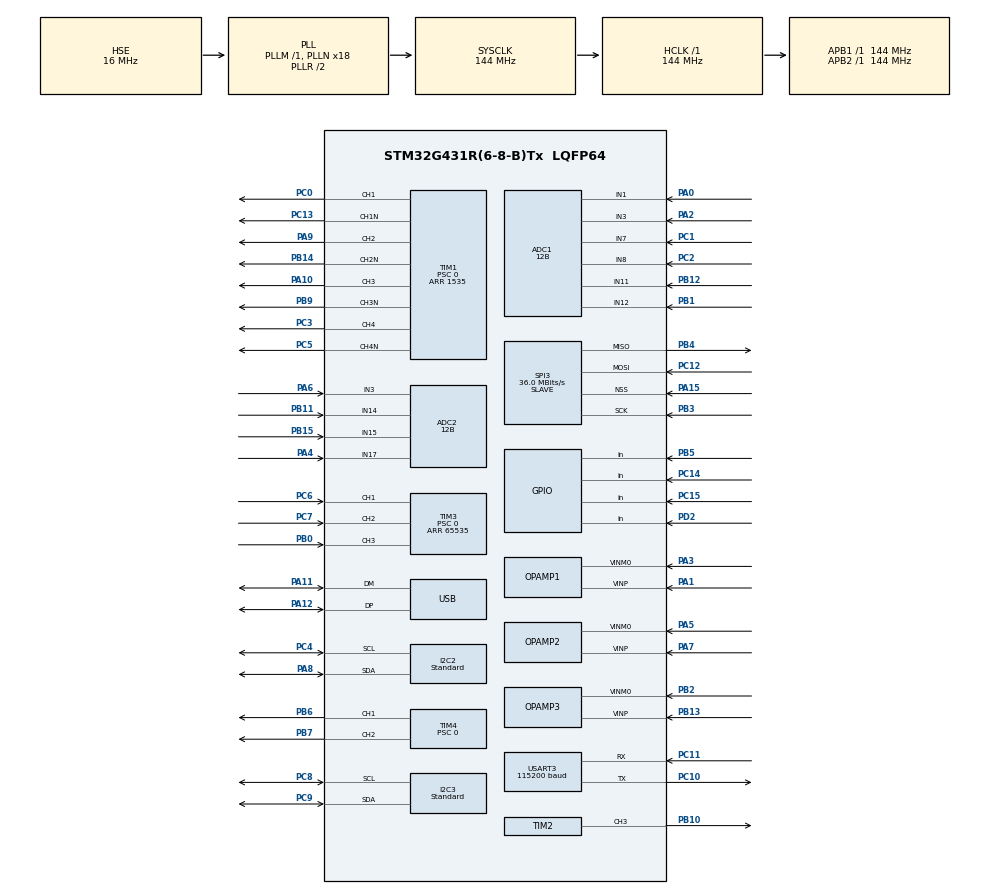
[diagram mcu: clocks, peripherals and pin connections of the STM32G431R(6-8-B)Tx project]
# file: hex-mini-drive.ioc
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ADC1.Channel-IN=ADC_CHANNEL_VOPAMP1
ADC1.Channel-IN1=ADC_CHANNEL_1
ADC1.Channel-IN11=ADC_CHANNEL_11
ADC1.Channel-IN12=ADC_CHANNEL_12
ADC1.Channel-IN3=ADC_CHANNEL_3
ADC1.Channel-IN7=ADC_CHANNEL_7
ADC1.Channel-IN8=ADC_CHANNEL_8
ADC1.ClockPrescaler=ADC_CLOCK_SYNC_PCLK_DIV4
ADC1.ContinuousConvMode=DISABLE
ADC1.DMAAccessModeView=DISABLED
ADC1.DMAContinuousRequests=DISABLE
ADC1.DataAlign=ADC_DATAALIGN_RIGHT
ADC1.DiscontinuousConvMode=DISABLE
ADC1.EOCSelection=ADC_EOC_SEQ_CONV
ADC1.EnableAnalogWatchDog1=false
ADC1.EnableAnalogWatchDog2=false
ADC1.EnableAnalogWatchDog3=false
ADC1.EnableInjectedConversion=ENABLE
ADC1.EnableInjectedOversampling=DISABLE
ADC1.EnableRegularConversion=DISABLE
ADC1.ExternalTrigInjecConv=ADC_EXTERNALTRIGINJEC_T1_TRGO2
ADC1.ExternalTrigInjecConvEdge=ADC_EXTERNALTRIGINJECCONV_EDGE_RISING
ADC1.GainCompensation=0
ADC1.InjNumberOfConversion=4
ADC1.InjectedChannel-1\#ChannelInjectedConversion=ADC_CHANNEL_TEMPSENSOR_ADC1
ADC1.InjectedChannel-2\#ChannelInjectedConversion=ADC_CHANNEL_1
ADC1.InjectedChannel-3\#ChannelInjectedConversion=ADC_CHANNEL_12
ADC1.InjectedChannel-4\#ChannelInjectedConversion=ADC_CHANNEL_3
ADC1.InjectedConvMode=None
ADC1.InjectedOffsetNumber-1\#ChannelInjectedConversion=ADC_OFFSET_NONE
ADC1.InjectedOffsetNumber-2\#ChannelInjectedConversion=ADC_OFFSET_NONE
ADC1.InjectedOffsetNumber-3\#ChannelInjectedConversion=ADC_OFFSET_NONE
ADC1.InjectedOffsetNumber-4\#ChannelInjectedConversion=ADC_OFFSET_NONE
ADC1.InjectedRank-1\#ChannelInjectedConversion=1
ADC1.InjectedRank-2\#ChannelInjectedConversion=2
ADC1.InjectedRank-3\#ChannelInjectedConversion=3
ADC1.InjectedRank-4\#ChannelInjectedConversion=4
ADC1.InjectedSamplingTime-1\#ChannelInjectedConversion=ADC_SAMPLETIME_92CYCLES_5
ADC1.InjectedSamplingTime-2\#ChannelInjectedConversion=ADC_SAMPLETIME_6CYCLES_5
ADC1.InjectedSamplingTime-3\#ChannelInjectedConversion=ADC_SAMPLETIME_6CYCLES_5
ADC1.InjectedSamplingTime-4\#ChannelInjectedConversion=ADC_SAMPLETIME_6CYCLES_5
ADC1.LowPowerAutoWait=DISABLE
ADC1.Mode=ADC_DUALMODE_REGSIMULT_INJECSIMULT
ADC1.Overrun=ADC_OVR_DATA_PRESERVED
ADC1.Resolution=ADC_RESOLUTION_12B
ADC1.ScanConvMode=ADC_SCAN_ENABLE
ADC1.TwoSamplingDelay=ADC_TWOSAMPLINGDELAY_1CYCLE
ADC1.injectedQueueMode=DISABLE
ADC1.master=1
ADC2.Channel-IN=ADC_CHANNEL_VOPAMP3_ADC2
ADC2.Channel-IN14=ADC_CHANNEL_14
ADC2.Channel-IN15=ADC_CHANNEL_15
ADC2.Channel-IN17=ADC_CHANNEL_17
ADC2.Channel-IN3=ADC_CHANNEL_3
ADC2.ClockPrescaler=ADC_CLOCK_SYNC_PCLK_DIV4
ADC2.ContinuousConvMode=DISABLE
ADC2.DMAAccessModeView=DISABLED
ADC2.DMAContinuousRequests=DISABLE
ADC2.DataAlign=ADC_DATAALIGN_RIGHT
ADC2.DiscontinuousConvMode=DISABLE
ADC2.EOCSelection=ADC_EOC_SINGLE_CONV
ADC2.EnableAnalogWatchDog1=false
ADC2.EnableAnalogWatchDog2=false
ADC2.EnableAnalogWatchDog3=false
ADC2.EnableInjectedConversion=ENABLE
ADC2.EnableInjectedOversampling=DISABLE
ADC2.EnableRegularConversion=DISABLE
ADC2.GainCompensation=0
ADC2.InjNumberOfConversion=4
ADC2.InjectedChannel-1\#ChannelInjectedConversion=ADC_CHANNEL_15
ADC2.InjectedChannel-2\#ChannelInjectedConversion=ADC_CHANNEL_3
ADC2.InjectedChannel-3\#ChannelInjectedConversion=ADC_CHANNEL_VOPAMP2
ADC2.InjectedChannel-4\#ChannelInjectedConversion=ADC_CHANNEL_VOPAMP3_ADC2
ADC2.InjectedConvMode=None
ADC2.InjectedOffsetNumber-1\#ChannelInjectedConversion=ADC_OFFSET_NONE
ADC2.InjectedOffsetNumber-2\#ChannelInjectedConversion=ADC_OFFSET_NONE
ADC2.InjectedOffsetNumber-3\#ChannelInjectedConversion=ADC_OFFSET_NONE
ADC2.InjectedOffsetNumber-4\#ChannelInjectedConversion=ADC_OFFSET_NONE
ADC2.InjectedRank-1\#ChannelInjectedConversion=1
ADC2.InjectedRank-2\#ChannelInjectedConversion=2
ADC2.InjectedRank-3\#ChannelInjectedConversion=3
ADC2.InjectedRank-4\#ChannelInjectedConversion=4
ADC2.InjectedSamplingTime-1\#ChannelInjectedConversion=ADC_SAMPLETIME_92CYCLES_5
ADC2.InjectedSamplingTime-2\#ChannelInjectedConversion=ADC_SAMPLETIME_6CYCLES_5
ADC2.InjectedSamplingTime-3\#ChannelInjectedConversion=ADC_SAMPLETIME_6CYCLES_5
ADC2.InjectedSamplingTime-4\#ChannelInjectedConversion=ADC_SAMPLETIME_6CYCLES_5
ADC2.LowPowerAutoWait=DISABLE
ADC2.Mode=ADC_DUALMODE_REGSIMULT_INJECSIMULT
ADC2.Overrun=ADC_OVR_DATA_PRESERVED
ADC2.Resolution=ADC_RESOLUTION_12B
ADC2.ScanConvMode=ADC_SCAN_ENABLE
ADC2.TwoSamplingDelay=ADC_TWOSAMPLINGDELAY_1CYCLE
ADC2.injectedQueueMode=DISABLE
I2C2.AddressingMode=I2C_ADDRESSINGMODE_7BIT
I2C2.Analog_Filter=I2C_ANALOGFILTER_ENABLE
I2C2.CustomTiming=Disabled
I2C2.DualAddressMode=I2C_DUALADDRESS_DISABLE
I2C2.GeneralCallMode=I2C_GENERALCALL_DISABLE
I2C2.I2C_Coeff_DF=0
I2C2.I2C_Fall_Time=100
I2C2.I2C_Rise_Time=100
I2C2.I2C_Speed_Mode=I2C_Standard
I2C2.NoStretchMode=I2C_NOSTRETCH_DISABLE
I2C2.OwnAddress=0
I2C2.Speed=100
I2C2.Timing=0x60715075
I2C3.AddressingMode=I2C_ADDRESSINGMODE_7BIT
I2C3.Analog_Filter=I2C_ANALOGFILTER_ENABLE
I2C3.CustomTiming=Disabled
I2C3.DualAddressMode=I2C_DUALADDRESS_DISABLE
I2C3.GeneralCallMode=I2C_GENERALCALL_DISABLE
I2C3.I2C_Coeff_DF=0
I2C3.I2C_Fall_Time=100
I2C3.I2C_Rise_Time=100
I2C3.I2C_Speed_Mode=I2C_Standard
I2C3.NoStretchMode=I2C_NOSTRETCH_DISABLE
I2C3.OwnAddress=0
I2C3.Speed=100
I2C3.Timing=0x60715075
Mcu.Family=STM32G4
Mcu.Name=STM32G431R(6-8-B)Tx
Mcu.Package=LQFP64
NVIC.ADC1_2_IRQn=true\:0\:0\:true\:false\:true\:true\:false\:true
NVIC.PriorityGroup=NVIC_PRIORITYGROUP_4
NVIC.TIM8_UP_IRQn=true\:15\:0\:false\:false\:true\:false\:true\:true
NVIC.TimeBase=TIM8_UP_IRQn
NVIC.TimeBaseIP=TIM8
NVIC.USB_LP_IRQn=true\:2\:0\:true\:false\:true\:false\:true\:true
OPAMP1.PgaGain=OPAMP_PGA_GAIN_2_OR_MINUS_1
OPAMP1.PowerMode=OPAMP_POWERMODE_NORMALSPEED
OPAMP2.PgaGain=OPAMP_PGA_GAIN_2_OR_MINUS_1
OPAMP2.PowerMode=OPAMP_POWERMODE_NORMALSPEED
OPAMP3.PgaGain=OPAMP_PGA_GAIN_2_OR_MINUS_1
OPAMP3.PowerMode=OPAMP_POWERMODE_NORMALSPEED
PA0.Mode=IN1-Single-Ended
PA0.Signal=ADC1_IN1
PA1.Mode=PGA Internally connected_IO0_BIAS
PA1.Signal=OPAMP1_VINP
PA10.Signal=S_TIM1_CH3
PA11.Mode=Device
PA11.Signal=USB_DM
PA12.Mode=Device
PA12.Signal=USB_DP
PA13.Mode=Serial_Wire
PA13.Signal=SYS_JTMS-SWDIO
PA14.Mode=Serial_Wire
PA14.Signal=SYS_JTCK-SWCLK
PA15.Mode=NSS_Signal_Hard_Input
PA15.Signal=SPI3_NSS
PA2.Mode=IN3-Single-Ended
PA2.Signal=ADC1_IN3
PA3.Mode=PGA Internally connected_IO0_BIAS
PA3.Signal=OPAMP1_VINM0
PA4.Mode=IN17-Single-Ended
PA4.Signal=ADC2_IN17
PA5.Mode=PGA Internally connected_IO0_BIAS
PA5.Signal=OPAMP2_VINM0
PA6.Mode=IN3-Single-Ended
PA6.Signal=ADC2_IN3
PA7.Mode=PGA Internally connected_IO0_BIAS
PA7.Signal=OPAMP2_VINP
PA8.Mode=I2C
PA8.Signal=I2C2_SDA
PA9.Signal=S_TIM1_CH2
PB0.GPIO_ModeDefaultPP=GPIO_MODE_AF_OD
PB0.GPIO_PuPd=GPIO_PULLUP
PB0.Signal=S_TIM3_CH3
PB1.Mode=IN12-Single-Ended
PB1.Signal=ADC1_IN12
PB10.Signal=S_TIM2_CH3
PB11.Mode=IN14-Single-Ended
PB11.Signal=ADC2_IN14
PB12.Mode=IN11-Single-Ended
PB12.Signal=ADC1_IN11
PB13.Mode=PGA Internally connected_IO0_BIAS
PB13.Signal=OPAMP3_VINP
PB14.GPIO_ModeDefaultPP=GPIO_MODE_AF_PP
PB14.GPIO_PuPd=GPIO_NOPULL
PB14.Mode=PWM Generation2 CH2 CH2N
PB14.Signal=TIM1_CH2N
PB15.Mode=IN15-Single-Ended
PB15.Signal=ADC2_IN15
PB2.Mode=PGA Internally connected_IO0_BIAS
PB2.Signal=OPAMP3_VINM0
PB3.Mode=Full_Duplex_Slave
PB3.Signal=SPI3_SCK
PB4.Mode=Full_Duplex_Slave
PB4.Signal=SPI3_MISO
PB5.Signal=GPIO_Input
PB6.Signal=S_TIM4_CH1
PB7.Signal=S_TIM4_CH2
PB9.Mode=PWM Generation3 CH3 CH3N
PB9.Signal=TIM1_CH3N
PC0.Signal=S_TIM1_CH1
PC1.Mode=IN7-Single-Ended
PC1.Signal=ADC1_IN7
PC10.Mode=Asynchronous
PC10.Signal=USART3_TX
PC11.Mode=Asynchronous
PC11.Signal=USART3_RX
PC12.Mode=Full_Duplex_Slave
PC12.Signal=SPI3_MOSI
PC13.Mode=PWM Generation1 CH1 CH1N
PC13.Signal=TIM1_CH1N
PC14-OSC32_IN.Signal=GPIO_Input
PC15-OSC32_OUT.Signal=GPIO_Input
PC2.Mode=IN8-Single-Ended
PC2.Signal=ADC1_IN8
PC3.Signal=S_TIM1_CH4
PC4.Mode=I2C
PC4.Signal=I2C2_SCL
PC5.Mode=PWM Generation4 CH4 CH4N
PC5.Signal=TIM1_CH4N
PC6.GPIO_ModeDefaultPP=GPIO_MODE_AF_OD
PC6.GPIO_PuPd=GPIO_PULLUP
PC6.Signal=S_TIM3_CH1
PC7.GPIO_ModeDefaultPP=GPIO_MODE_AF_OD
PC7.GPIO_PuPd=GPIO_PULLUP
PC7.Signal=S_TIM3_CH2
PC8.Mode=I2C
PC8.Signal=I2C3_SCL
PC9.Mode=I2C
PC9.Signal=I2C3_SDA
PD2.Signal=GPIO_Input
PF0-OSC_IN.Mode=HSE-External-Oscillator
PF0-OSC_IN.Signal=RCC_OSC_IN
PF1-OSC_OUT.Mode=HSE-External-Oscillator
PF1-OSC_OUT.Signal=RCC_OSC_OUT
ProjectManager.HeapSize=0x200
ProjectManager.StackSize=0x400
ProjectManager.TargetToolchain=CMake
RCC.ADC12Freq_Value=144000000
RCC.AHBFreq_Value=144000000
RCC.APB1Freq_Value=144000000
RCC.APB1TimFreq_Value=144000000
RCC.APB2Freq_Value=144000000
RCC.APB2TimFreq_Value=144000000
RCC.CortexFreq_Value=144000000
RCC.EXTERNAL_CLOCK_VALUE=12288000
RCC.HCLKFreq_Value=144000000
RCC.HSE_VALUE=16000000
RCC.HSI48_VALUE=48000000
RCC.HSI_VALUE=16000000
RCC.LSE_VALUE=32768
RCC.PLLN=18
RCC.PLLQ=RCC_PLLQ_DIV6
RCC.PLLSourceVirtual=RCC_PLLSOURCE_HSE
RCC.SYSCLKFreq_VALUE=144000000
RCC.SYSCLKSource=RCC_SYSCLKSOURCE_PLLCLK
RCC.USBFreq_Value=48000000
RCC.VCOOutputFreq_Value=288000000
SH.S_TIM1_CH1.0=TIM1_CH1,PWM Generation1 CH1 CH1N
SH.S_TIM1_CH2.0=TIM1_CH2,PWM Generation2 CH2 CH2N
SH.S_TIM1_CH3.0=TIM1_CH3,PWM Generation3 CH3 CH3N
SH.S_TIM1_CH4.0=TIM1_CH4,PWM Generation4 CH4 CH4N
SH.S_TIM2_CH3.0=TIM2_CH3,PWM Generation3 CH3
SH.S_TIM3_CH1.0=TIM3_CH1,Xored_Inputs_Hall_Sensor_Interface
SH.S_TIM3_CH2.0=TIM3_CH2,Xored_Inputs_Hall_Sensor_Interface
SH.S_TIM3_CH3.0=TIM3_CH3,Xored_Inputs_Hall_Sensor_Interface
SH.S_TIM4_CH1.0=TIM4_CH1,PWM Generation1 CH1
SH.S_TIM4_CH2.0=TIM4_CH2,PWM Generation2 CH2
SPI3.BaudRatePrescaler=SPI_BAUDRATEPRESCALER_4
SPI3.CRCCalculation=SPI_CRCCALCULATION_DISABLE
SPI3.CalculateBaudRate=36.0 MBits/s
SPI3.DataSize=SPI_DATASIZE_8BIT
SPI3.Direction=SPI_DIRECTION_2LINES
SPI3.Mode=SPI_MODE_SLAVE
SPI3.NSS=SPI_NSS_HARD_INPUT
SPI3.TIMode=SPI_TIMODE_ENABLE
SPI3.TIMode-Full_Duplex_Slave=SPI_TIMODE_ENABLE
SPI3.VirtualNSS=VM_NSSHARD
SPI3.VirtualType=VM_SLAVE
SYS.PVDLevel=PWR_PVDLEVEL_6
TIM1.AsymmetricalDeadTime=DISABLE
TIM1.AutoReloadPreload=TIM_AUTORELOAD_PRELOAD_ENABLE
TIM1.AutomaticOutput=TIM_AUTOMATICOUTPUT_DISABLE
TIM1.Break2Filter=0
TIM1.Break2Polarity=TIM_BREAK2POLARITY_HIGH
TIM1.Break2State=TIM_BREAK2_DISABLE
TIM1.BreakFilter=0
TIM1.BreakPolarity=TIM_BREAKPOLARITY_HIGH
TIM1.BreakState=TIM_BREAK_DISABLE
TIM1.Channel-PWM\ Generation1\ CH1\ CH1N=TIM_CHANNEL_1
TIM1.Channel-PWM\ Generation2\ CH2\ CH2N=TIM_CHANNEL_2
TIM1.Channel-PWM\ Generation3\ CH3\ CH3N=TIM_CHANNEL_3
TIM1.Channel-PWM\ Generation4\ CH4\ CH4N=TIM_CHANNEL_4
TIM1.Channel-PWM\ Generation5\ No\ Output=TIM_CHANNEL_5
TIM1.Channel-PWM\ Generation6\ No\ Output=TIM_CHANNEL_6
TIM1.ClearInputSource=TIM_CLEARINPUTSOURCE_NONE
TIM1.ClockDivision=TIM_CLOCKDIVISION_DIV1
TIM1.CounterMode=TIM_COUNTERMODE_CENTERALIGNED1
TIM1.DeadTime=0
TIM1.DeadTimePreload=DISABLE
TIM1.Dithering=Disable
TIM1.LockLevel=TIM_LOCKLEVEL_OFF
TIM1.OC1Preload_PWM=ENABLE
TIM1.OC2Preload_PWM=ENABLE
TIM1.OC3Preload_PWM=ENABLE
TIM1.OC4Preload_PWM=ENABLE
TIM1.OC5Preload_PWM=ENABLE
TIM1.OC6Preload_PWM=ENABLE
TIM1.OCFastMode_PWM-PWM\ Generation1\ CH1\ CH1N=TIM_OCFAST_DISABLE
TIM1.OCFastMode_PWM-PWM\ Generation2\ CH2\ CH2N=TIM_OCFAST_DISABLE
TIM1.OCFastMode_PWM-PWM\ Generation3\ CH3\ CH3N=TIM_OCFAST_DISABLE
TIM1.OCFastMode_PWM-PWM\ Generation4\ CH4\ CH4N=TIM_OCFAST_DISABLE
TIM1.OCFastMode_PWM-PWM\ Generation5\ No\ Output=TIM_OCFAST_DISABLE
TIM1.OCFastMode_PWM-PWM\ Generation6\ No\ Output=TIM_OCFAST_DISABLE
TIM1.OCIdleState_1=TIM_OCIDLESTATE_RESET
TIM1.OCIdleState_2=TIM_OCIDLESTATE_RESET
TIM1.OCIdleState_3=TIM_OCIDLESTATE_RESET
TIM1.OCIdleState_4=TIM_OCIDLESTATE_RESET
TIM1.OCIdleState_5=TIM_OCIDLESTATE_RESET
TIM1.OCIdleState_6=TIM_OCIDLESTATE_RESET
TIM1.OCMode_PWM-PWM\ Generation1\ CH1\ CH1N=TIM_OCMODE_PWM1
TIM1.OCMode_PWM-PWM\ Generation2\ CH2\ CH2N=TIM_OCMODE_PWM1
TIM1.OCMode_PWM-PWM\ Generation3\ CH3\ CH3N=TIM_OCMODE_PWM1
TIM1.OCMode_PWM-PWM\ Generation4\ CH4\ CH4N=TIM_OCMODE_PWM1
TIM1.OCMode_PWM-PWM\ Generation5\ No\ Output=TIM_OCMODE_PWM1
TIM1.OCMode_PWM-PWM\ Generation6\ No\ Output=TIM_OCMODE_PWM1
TIM1.OCNIdleState_1=TIM_OCNIDLESTATE_RESET
TIM1.OCNIdleState_2=TIM_OCNIDLESTATE_RESET
TIM1.OCNIdleState_3=TIM_OCNIDLESTATE_RESET
TIM1.OCNIdleState_4=TIM_OCNIDLESTATE_RESET
TIM1.OCNPolarity_1=TIM_OCNPOLARITY_HIGH
TIM1.OCNPolarity_2=TIM_OCNPOLARITY_HIGH
TIM1.OCNPolarity_3=TIM_OCNPOLARITY_HIGH
TIM1.OCNPolarity_4=TIM_OCNPOLARITY_HIGH
TIM1.OCPolarity_1=TIM_OCPOLARITY_HIGH
TIM1.OCPolarity_2=TIM_OCPOLARITY_HIGH
TIM1.OCPolarity_3=TIM_OCPOLARITY_HIGH
TIM1.OCPolarity_4=TIM_OCPOLARITY_HIGH
TIM1.OCPolarity_5=TIM_OCPOLARITY_HIGH
TIM1.OCPolarity_6=TIM_OCPOLARITY_HIGH
TIM1.OffStateIDLEMode=TIM_OSSI_DISABLE
TIM1.OffStateRunMode=TIM_OSSR_DISABLE
TIM1.PeriodNoDither=1535
TIM1.Prescaler=0
TIM1.PulseNoDither_1=0
TIM1.PulseNoDither_2=0
TIM1.PulseNoDither_3=0
TIM1.PulseNoDither_4=0
TIM1.PulseNoDither_5=0
TIM1.PulseNoDither_6=0
TIM1.RepetitionCounter=0
TIM1.SourceBRK2COMP1=TIM_BREAKINPUTSOURCE_DISABLE
TIM1.SourceBRK2COMP2=TIM_BREAKINPUTSOURCE_DISABLE
TIM1.SourceBRK2COMP3=TIM_BREAKINPUTSOURCE_DISABLE
TIM1.SourceBRK2COMP4=TIM_BREAKINPUTSOURCE_DISABLE
TIM1.SourceBRK2DigInput=TIM_BREAKINPUTSOURCE_DISABLE
TIM1.SourceBRKCOMP1=TIM_BREAKINPUTSOURCE_DISABLE
TIM1.SourceBRKCOMP2=TIM_BREAKINPUTSOURCE_DISABLE
TIM1.SourceBRKCOMP3=TIM_BREAKINPUTSOURCE_DISABLE
TIM1.SourceBRKCOMP4=TIM_BREAKINPUTSOURCE_DISABLE
TIM1.SourceBRKDigInput=TIM_BREAKINPUTSOURCE_DISABLE
TIM1.TIM_MasterOutputTrigger=TIM_TRGO_RESET
TIM1.TIM_MasterOutputTrigger2=TIM_TRGO2_OC5REF
TIM1.TIM_MasterSlaveMode=TIM_MASTERSLAVEMODE_DISABLE
TIM2.AutoReloadPreload=TIM_AUTORELOAD_PRELOAD_DISABLE
TIM2.Channel-PWM\ Generation3\ CH3=TIM_CHANNEL_3
TIM2.ClearInputSource=TIM_CLEARINPUTSOURCE_NONE
TIM2.ClockDivision=TIM_CLOCKDIVISION_DIV1
TIM2.CounterMode=TIM_COUNTERMODE_UP
TIM2.Dithering=Disable
TIM2.OC3Preload_PWM=ENABLE
TIM2.OCFastMode_PWM-PWM\ Generation3\ CH3=TIM_OCFAST_DISABLE
TIM2.OCMode_PWM-PWM\ Generation3\ CH3=TIM_OCMODE_PWM1
TIM2.OCPolarity_3=TIM_OCPOLARITY_LOW
TIM2.PeriodNoDither=65535
TIM2.Prescaler=0
TIM2.PulseNoDither_3=0
TIM2.TIM_MasterOutputTrigger=TIM_TRGO_RESET
TIM2.TIM_MasterSlaveMode=TIM_MASTERSLAVEMODE_DISABLE
TIM3.AutoReloadPreload=TIM_AUTORELOAD_PRELOAD_DISABLE
TIM3.ClockDivision=TIM_CLOCKDIVISION_DIV1
TIM3.Commutation_Delay=0
TIM3.CounterMode=TIM_COUNTERMODE_UP
TIM3.Dithering=Disable
TIM3.IC1Filter=0
TIM3.IC1Polarity=TIM_ICPOLARITY_RISING
TIM3.IC1Prescaler=TIM_ICPSC_DIV1
TIM3.PeriodNoDither=65535
TIM3.Prescaler=0
TIM3.TIM_MasterOutputTrigger=TIM_TRGO_OC2REF
TIM4.AutoReloadPreload=TIM_AUTORELOAD_PRELOAD_DISABLE
TIM4.Channel-PWM\ Generation1\ CH1=TIM_CHANNEL_1
TIM4.Channel-PWM\ Generation2\ CH2=TIM_CHANNEL_2
TIM4.ClearInputSource=TIM_CLEARINPUTSOURCE_NONE
TIM4.ClockDivision=TIM_CLOCKDIVISION_DIV1
TIM4.CounterMode=TIM_COUNTERMODE_UP
TIM4.Dithering=Disable
TIM4.OC1Preload_PWM=ENABLE
TIM4.OC2Preload_PWM=ENABLE
TIM4.OCFastMode_PWM-PWM\ Generation1\ CH1=TIM_OCFAST_DISABLE
TIM4.OCFastMode_PWM-PWM\ Generation2\ CH2=TIM_OCFAST_DISABLE
TIM4.OCMode_PWM-PWM\ Generation1\ CH1=TIM_OCMODE_PWM1
TIM4.OCMode_PWM-PWM\ Generation2\ CH2=TIM_OCMODE_PWM1
TIM4.OCPolarity_1=TIM_OCPOLARITY_LOW
TIM4.OCPolarity_2=TIM_OCPOLARITY_LOW
TIM4.PeriodNoDither=65535
TIM4.Prescaler=0
TIM4.PulseNoDither_1=0
TIM4.PulseNoDither_2=0
TIM4.TIM_MasterOutputTrigger=TIM_TRGO_RESET
TIM4.TIM_MasterSlaveMode=TIM_MASTERSLAVEMODE_DISABLE
USART3.AutoBaudRateEnableParam=UART_ADVFEATURE_AUTOBAUDRATE_DISABLE
USART3.BaudRate=115200
USART3.ClockPrescaler=PRESCALER_DIV1
USART3.DMADisableonRxErrorParam=ADVFEATURE_DMA_ENABLEONRXERROR
USART3.DataInvertParam=ADVFEATURE_DATAINV_DISABLE
USART3.FIFOMode=FIFOMODE_DISABLE
USART3.MSBFirstParam=ADVFEATURE_MSBFIRST_DISABLE
USART3.Mode=MODE_TX_RX
USART3.OneBitSampling=UART_ONE_BIT_SAMPLE_DISABLE
USART3.OverSampling=UART_OVERSAMPLING_16
USART3.OverrunDisableParam=ADVFEATURE_OVERRUN_ENABLE
USART3.Parity=PARITY_NONE
USART3.RXFIFOThreshold=RXFIFO_THRESHOLD_1EIGHTHFULL
USART3.RxPinLevelInvertParam=ADVFEATURE_RXINV_DISABLE
USART3.StopBits=STOPBITS_1
USART3.SwapParam=ADVFEATURE_SWAP_DISABLE
USART3.TXFIFOThreshold=TXFIFO_THRESHOLD_1EIGHTHFULL
USART3.TxPinLevelInvertParam=ADVFEATURE_TXINV_DISABLE
USART3.VirtualMode-Asynchronous=VM_ASYNC
USART3.WordLength=WORDLENGTH_8B
USB_DEVICE.APP_RX_DATA_SIZE=1024
USB_DEVICE.APP_TX_DATA_SIZE=1024
USB_DEVICE.CLASS_NAME_FS=CDC
USB_DEVICE.CONFIGURATION_STRING_CDC_FS=CDC Config
USB_DEVICE.INTERFACE_STRING_CDC_FS=CDC Interface
USB_DEVICE.LANGID_STRING=1033
USB_DEVICE.MANUFACTURER_STRING=HexRobotics
USB_DEVICE.PID_CDC_FS=56988
USB_DEVICE.PRODUCT_STRING_CDC_FS=Hex-driver Virtual ComPort
USB_DEVICE.USBD_DEBUG_LEVEL=0
USB_DEVICE.USBD_LPM_ENABLED=1
USB_DEVICE.USBD_MAX_NUM_CONFIGURATION=1
USB_DEVICE.USBD_MAX_NUM_INTERFACES=1
USB_DEVICE.USBD_MAX_STR_DESC_SIZ=512
USB_DEVICE.USBD_SELF_POWERED=1
USB_DEVICE.VID=56987
USB_DEVICE.VirtualMode=Cdc
USB_DEVICE.VirtualModeFS=Cdc_FS
VP_ADC1_OPAMP_INTERNAL1.Mode=IN-OPAMP1
VP_ADC1_TempSens_Input.Mode=IN-TempSens
VP_ADC1_Vref_Input.Mode=IN-Vrefint
VP_ADC2_OPAMP_INTERNAL2.Mode=IN-OPAMP2
VP_ADC2_OPAMP_INTERNAL3.Mode=IN-OPAMP3
VP_SYS_VS_DBSignals.Mode=DisableDeadBatterySignals
VP_SYS_VS_tim8.Mode=TIM8
VP_SYS_V_PVD_IN.Mode=Mode_PVD_Int
VP_SYS_V_VREFBUF.Mode=ExternalMode
VP_TIM1_VS_ClockSourceINT.Mode=Internal
VP_TIM1_VS_no_output5.Mode=PWM Generation5 No Output
VP_TIM1_VS_no_output6.Mode=PWM Generation6 No Output
VP_TIM2_VS_ClockSourceINT.Mode=Internal
VP_TIM3_VS_ClockSourceINT.Mode=Internal
VP_TIM4_VS_ClockSourceINT.Mode=Internal
VP_USB_DEVICE_VS_USB_DEVICE_CDC_FS.Mode=CDC_FS
board=custom

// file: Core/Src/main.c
/* USER CODE BEGIN Header */
/**
  ******************************************************************************
  * @file           : main.c
  * @brief          : Main program body
  ******************************************************************************
  * @attention
  *
  * Copyright (c) 2025 STMicroelectronics.
  * All rights reserved.
  *
  * This software is licensed under terms that can be found in the LICENSE file
  * in the root directory of this software component.
  * If no LICENSE file comes with this software, it is provided AS-IS.
  *
  ******************************************************************************
  */
/* USER CODE END Header */
#include "main.h"
#include "usb_device.h"

/* USER CODE BEGIN Includes */
#include "app_main.hpp"
#include "error_handler.hpp"
/* USER CODE END Includes */

ADC_HandleTypeDef hadc1;
ADC_HandleTypeDef hadc2;

I2C_HandleTypeDef hi2c2;
I2C_HandleTypeDef hi2c3;

OPAMP_HandleTypeDef hopamp1;
OPAMP_HandleTypeDef hopamp2;
OPAMP_HandleTypeDef hopamp3;

SPI_HandleTypeDef hspi3;

TIM_HandleTypeDef htim1;
TIM_HandleTypeDef htim2;
TIM_HandleTypeDef htim3;
TIM_HandleTypeDef htim4;

UART_HandleTypeDef huart3;

void SystemClock_Config(void);
static void MX_GPIO_Init(void);
static void MX_ADC1_Init(void);
static void MX_ADC2_Init(void);
static void MX_I2C2_Init(void);
static void MX_OPAMP1_Init(void);
static void MX_OPAMP2_Init(void);
static void MX_OPAMP3_Init(void);
static void MX_TIM1_Init(void);
static void MX_TIM2_Init(void);
static void MX_SPI3_Init(void);
static void MX_TIM3_Init(void);
static void MX_I2C3_Init(void);
static void MX_TIM4_Init(void);
static void MX_USART3_UART_Init(void);

int main(void)
{

  /* MCU Configuration--------------------------------------------------------*/

  /* Reset of all peripherals, Initializes the Flash interface and the Systick. */
  HAL_Init();

  /* Configure the system clock */
  SystemClock_Config();

  /* Initialize all configured peripherals */
  MX_GPIO_Init();
  MX_ADC1_Init();
  MX_ADC2_Init();
  MX_I2C2_Init();
  MX_OPAMP1_Init();
  MX_OPAMP2_Init();
  MX_OPAMP3_Init();
  MX_TIM1_Init();
  MX_TIM2_Init();
  MX_SPI3_Init();
  MX_TIM3_Init();
  MX_I2C3_Init();
  MX_TIM4_Init();
  MX_USART3_UART_Init();
  MX_USB_Device_Init();

  /* Infinite loop */
  /* USER CODE BEGIN WHILE */
  app_init();
  while (1) {
    /* USER CODE END WHILE */

    /* USER CODE BEGIN 3 */
    app_tick();
  }
  /* USER CODE END 3 */
}

void SystemClock_Config(void)
{
  RCC_OscInitTypeDef RCC_OscInitStruct = {0};
  RCC_ClkInitTypeDef RCC_ClkInitStruct = {0};

  /** Configure the main internal regulator output voltage
  */
  HAL_PWREx_ControlVoltageScaling(PWR_REGULATOR_VOLTAGE_SCALE1);

  /** Initializes the RCC Oscillators according to the specified parameters
  * in the RCC_OscInitTypeDef structure.
  */
  RCC_OscInitStruct.OscillatorType = RCC_OSCILLATORTYPE_HSE;
  RCC_OscInitStruct.HSEState = RCC_HSE_ON;
  RCC_OscInitStruct.PLL.PLLState = RCC_PLL_ON;
  RCC_OscInitStruct.PLL.PLLSource = RCC_PLLSOURCE_HSE;
  RCC_OscInitStruct.PLL.PLLM = RCC_PLLM_DIV1;
  RCC_OscInitStruct.PLL.PLLN = 18;
  RCC_OscInitStruct.PLL.PLLP = RCC_PLLP_DIV2;
  RCC_OscInitStruct.PLL.PLLQ = RCC_PLLQ_DIV6;
  RCC_OscInitStruct.PLL.PLLR = RCC_PLLR_DIV2;
  if (HAL_RCC_OscConfig(&RCC_OscInitStruct) != HAL_OK)
  {
    Error_Handler();
  }

  /** Initializes the CPU, AHB and APB buses clocks
  */
  RCC_ClkInitStruct.ClockType = RCC_CLOCKTYPE_HCLK|RCC_CLOCKTYPE_SYSCLK
                              |RCC_CLOCKTYPE_PCLK1|RCC_CLOCKTYPE_PCLK2;
  RCC_ClkInitStruct.SYSCLKSource = RCC_SYSCLKSOURCE_PLLCLK;
  RCC_ClkInitStruct.AHBCLKDivider = RCC_SYSCLK_DIV1;
  RCC_ClkInitStruct.APB1CLKDivider = RCC_HCLK_DIV1;
  RCC_ClkInitStruct.APB2CLKDivider = RCC_HCLK_DIV1;

  if (HAL_RCC_ClockConfig(&RCC_ClkInitStruct, FLASH_LATENCY_4) != HAL_OK)
  {
    Error_Handler();
  }
}

static void MX_ADC1_Init(void)
{

  ADC_MultiModeTypeDef multimode = {0};
  ADC_InjectionConfTypeDef sConfigInjected = {0};

  /** Common config
  */
  hadc1.Instance = ADC1;
  hadc1.Init.ClockPrescaler = ADC_CLOCK_SYNC_PCLK_DIV4;
  hadc1.Init.Resolution = ADC_RESOLUTION_12B;
  hadc1.Init.DataAlign = ADC_DATAALIGN_RIGHT;
  hadc1.Init.GainCompensation = 0;
  hadc1.Init.ScanConvMode = ADC_SCAN_ENABLE;
  hadc1.Init.EOCSelection = ADC_EOC_SEQ_CONV;
  hadc1.Init.LowPowerAutoWait = DISABLE;
  hadc1.Init.ContinuousConvMode = DISABLE;
  hadc1.Init.NbrOfConversion = 1;
  hadc1.Init.DiscontinuousConvMode = DISABLE;
  hadc1.Init.DMAContinuousRequests = DISABLE;
  hadc1.Init.Overrun = ADC_OVR_DATA_PRESERVED;
  hadc1.Init.OversamplingMode = DISABLE;
  if (HAL_ADC_Init(&hadc1) != HAL_OK)
  {
    Error_Handler();
  }

  /** Configure the ADC multi-mode
  */
  multimode.Mode = ADC_DUALMODE_REGSIMULT_INJECSIMULT;
  multimode.DMAAccessMode = ADC_DMAACCESSMODE_DISABLED;
  multimode.TwoSamplingDelay = ADC_TWOSAMPLINGDELAY_1CYCLE;
  if (HAL_ADCEx_MultiModeConfigChannel(&hadc1, &multimode) != HAL_OK)
  {
    Error_Handler();
  }

  /** Configure Injected Channel
  */
  sConfigInjected.InjectedChannel = ADC_CHANNEL_TEMPSENSOR_ADC1;
  sConfigInjected.InjectedRank = ADC_INJECTED_RANK_1;
  sConfigInjected.InjectedSamplingTime = ADC_SAMPLETIME_92CYCLES_5;
  sConfigInjected.InjectedSingleDiff = ADC_SINGLE_ENDED;
  sConfigInjected.InjectedOffsetNumber = ADC_OFFSET_NONE;
  sConfigInjected.InjectedOffset = 0;
  sConfigInjected.InjectedNbrOfConversion = 4;
  sConfigInjected.InjectedDiscontinuousConvMode = DISABLE;
  sConfigInjected.AutoInjectedConv = DISABLE;
  sConfigInjected.QueueInjectedContext = DISABLE;
  sConfigInjected.ExternalTrigInjecConv = ADC_EXTERNALTRIGINJEC_T1_TRGO2;
  sConfigInjected.ExternalTrigInjecConvEdge = ADC_EXTERNALTRIGINJECCONV_EDGE_RISING;
  sConfigInjected.InjecOversamplingMode = DISABLE;
  if (HAL_ADCEx_InjectedConfigChannel(&hadc1, &sConfigInjected) != HAL_OK)
  {
    Error_Handler();
  }

  /** Configure Injected Channel
  */
  sConfigInjected.InjectedChannel = ADC_CHANNEL_1;
  sConfigInjected.InjectedRank = ADC_INJECTED_RANK_2;
  sConfigInjected.InjectedSamplingTime = ADC_SAMPLETIME_6CYCLES_5;
  if (HAL_ADCEx_InjectedConfigChannel(&hadc1, &sConfigInjected) != HAL_OK)
  {
    Error_Handler();
  }

  /** Configure Injected Channel
  */
  sConfigInjected.InjectedChannel = ADC_CHANNEL_12;
  sConfigInjected.InjectedRank = ADC_INJECTED_RANK_3;
  if (HAL_ADCEx_InjectedConfigChannel(&hadc1, &sConfigInjected) != HAL_OK)
  {
    Error_Handler();
  }

  /** Configure Injected Channel
  */
  sConfigInjected.InjectedChannel = ADC_CHANNEL_3;
  sConfigInjected.InjectedRank = ADC_INJECTED_RANK_4;
  if (HAL_ADCEx_InjectedConfigChannel(&hadc1, &sConfigInjected) != HAL_OK)
  {
    Error_Handler();
  }

}

static void MX_ADC2_Init(void)
{

  ADC_InjectionConfTypeDef sConfigInjected = {0};

  /** Common config
  */
  hadc2.Instance = ADC2;
  hadc2.Init.ClockPrescaler = ADC_CLOCK_SYNC_PCLK_DIV4;
  hadc2.Init.Resolution = ADC_RESOLUTION_12B;
  hadc2.Init.DataAlign = ADC_DATAALIGN_RIGHT;
  hadc2.Init.GainCompensation = 0;
  hadc2.Init.ScanConvMode = ADC_SCAN_ENABLE;
  hadc2.Init.EOCSelection = ADC_EOC_SINGLE_CONV;
  hadc2.Init.LowPowerAutoWait = DISABLE;
  hadc2.Init.ContinuousConvMode = DISABLE;
  hadc2.Init.NbrOfConversion = 1;
  hadc2.Init.DiscontinuousConvMode = DISABLE;
  hadc2.Init.DMAContinuousRequests = DISABLE;
  hadc2.Init.Overrun = ADC_OVR_DATA_PRESERVED;
  hadc2.Init.OversamplingMode = DISABLE;
  if (HAL_ADC_Init(&hadc2) != HAL_OK)
  {
    Error_Handler();
  }

  /** Configure Injected Channel
  */
  sConfigInjected.InjectedChannel = ADC_CHANNEL_15;
  sConfigInjected.InjectedRank = ADC_INJECTED_RANK_1;
  sConfigInjected.InjectedSamplingTime = ADC_SAMPLETIME_92CYCLES_5;
  sConfigInjected.InjectedSingleDiff = ADC_SINGLE_ENDED;
  sConfigInjected.InjectedOffsetNumber = ADC_OFFSET_NONE;
  sConfigInjected.InjectedOffset = 0;
  sConfigInjected.InjectedNbrOfConversion = 4;
  sConfigInjected.InjectedDiscontinuousConvMode = DISABLE;
  sConfigInjected.AutoInjectedConv = DISABLE;
  sConfigInjected.QueueInjectedContext = DISABLE;
  sConfigInjected.InjecOversamplingMode = DISABLE;
  if (HAL_ADCEx_InjectedConfigChannel(&hadc2, &sConfigInjected) != HAL_OK)
  {
    Error_Handler();
  }

  /** Configure Injected Channel
  */
  sConfigInjected.InjectedChannel = ADC_CHANNEL_3;
  sConfigInjected.InjectedRank = ADC_INJECTED_RANK_2;
  sConfigInjected.InjectedSamplingTime = ADC_SAMPLETIME_6CYCLES_5;
  if (HAL_ADCEx_InjectedConfigChannel(&hadc2, &sConfigInjected) != HAL_OK)
  {
    Error_Handler();
  }

  /** Configure Injected Channel
  */
  sConfigInjected.InjectedChannel = ADC_CHANNEL_VOPAMP2;
  sConfigInjected.InjectedRank = ADC_INJECTED_RANK_3;
  if (HAL_ADCEx_InjectedConfigChannel(&hadc2, &sConfigInjected) != HAL_OK)
  {
    Error_Handler();
  }

  /** Configure Injected Channel
  */
  sConfigInjected.InjectedChannel = ADC_CHANNEL_VOPAMP3_ADC2;
  sConfigInjected.InjectedRank = ADC_INJECTED_RANK_4;
  if (HAL_ADCEx_InjectedConfigChannel(&hadc2, &sConfigInjected) != HAL_OK)
  {
    Error_Handler();
  }

}

static void MX_I2C2_Init(void)
{

  hi2c2.Instance = I2C2;
  hi2c2.Init.Timing = 0x60715075;
  hi2c2.Init.OwnAddress1 = 0;
  hi2c2.Init.AddressingMode = I2C_ADDRESSINGMODE_7BIT;
  hi2c2.Init.DualAddressMode = I2C_DUALADDRESS_DISABLE;
  hi2c2.Init.OwnAddress2 = 0;
  hi2c2.Init.OwnAddress2Masks = I2C_OA2_NOMASK;
  hi2c2.Init.GeneralCallMode = I2C_GENERALCALL_DISABLE;
  hi2c2.Init.NoStretchMode = I2C_NOSTRETCH_DISABLE;
  if (HAL_I2C_Init(&hi2c2) != HAL_OK)
  {
    Error_Handler();
  }

  /** Configure Analogue filter
  */
  if (HAL_I2CEx_ConfigAnalogFilter(&hi2c2, I2C_ANALOGFILTER_ENABLE) != HAL_OK)
  {
    Error_Handler();
  }

  /** Configure Digital filter
  */
  if (HAL_I2CEx_ConfigDigitalFilter(&hi2c2, 0) != HAL_OK)
  {
    Error_Handler();
  }

}

static void MX_I2C3_Init(void)
{

  hi2c3.Instance = I2C3;
  hi2c3.Init.Timing = 0x60715075;
  hi2c3.Init.OwnAddress1 = 0;
  hi2c3.Init.AddressingMode = I2C_ADDRESSINGMODE_7BIT;
  hi2c3.Init.DualAddressMode = I2C_DUALADDRESS_DISABLE;
  hi2c3.Init.OwnAddress2 = 0;
  hi2c3.Init.OwnAddress2Masks = I2C_OA2_NOMASK;
  hi2c3.Init.GeneralCallMode = I2C_GENERALCALL_DISABLE;
  hi2c3.Init.NoStretchMode = I2C_NOSTRETCH_DISABLE;
  if (HAL_I2C_Init(&hi2c3) != HAL_OK)
  {
    Error_Handler();
  }

  /** Configure Analogue filter
  */
  if (HAL_I2CEx_ConfigAnalogFilter(&hi2c3, I2C_ANALOGFILTER_ENABLE) != HAL_OK)
  {
    Error_Handler();
  }

  /** Configure Digital filter
  */
  if (HAL_I2CEx_ConfigDigitalFilter(&hi2c3, 0) != HAL_OK)
  {
    Error_Handler();
  }

}

static void MX_OPAMP1_Init(void)
{

  hopamp1.Instance = OPAMP1;
  hopamp1.Init.PowerMode = OPAMP_POWERMODE_NORMALSPEED;
  hopamp1.Init.Mode = OPAMP_PGA_MODE;
  hopamp1.Init.NonInvertingInput = OPAMP_NONINVERTINGINPUT_IO0;
  hopamp1.Init.InternalOutput = ENABLE;
  hopamp1.Init.TimerControlledMuxmode = OPAMP_TIMERCONTROLLEDMUXMODE_DISABLE;
  hopamp1.Init.PgaConnect = OPAMP_PGA_CONNECT_INVERTINGINPUT_IO0_BIAS;
  hopamp1.Init.PgaGain = OPAMP_PGA_GAIN_2_OR_MINUS_1;
  hopamp1.Init.UserTrimming = OPAMP_TRIMMING_FACTORY;
  if (HAL_OPAMP_Init(&hopamp1) != HAL_OK)
  {
    Error_Handler();
  }

}

static void MX_OPAMP2_Init(void)
{

  hopamp2.Instance = OPAMP2;
  hopamp2.Init.PowerMode = OPAMP_POWERMODE_NORMALSPEED;
  hopamp2.Init.Mode = OPAMP_PGA_MODE;
  hopamp2.Init.NonInvertingInput = OPAMP_NONINVERTINGINPUT_IO0;
  hopamp2.Init.InternalOutput = ENABLE;
  hopamp2.Init.TimerControlledMuxmode = OPAMP_TIMERCONTROLLEDMUXMODE_DISABLE;
  hopamp2.Init.PgaConnect = OPAMP_PGA_CONNECT_INVERTINGINPUT_IO0_BIAS;
  hopamp2.Init.PgaGain = OPAMP_PGA_GAIN_2_OR_MINUS_1;
  hopamp2.Init.UserTrimming = OPAMP_TRIMMING_FACTORY;
  if (HAL_OPAMP_Init(&hopamp2) != HAL_OK)
  {
    Error_Handler();
  }

}

static void MX_OPAMP3_Init(void)
{

  hopamp3.Instance = OPAMP3;
  hopamp3.Init.PowerMode = OPAMP_POWERMODE_NORMALSPEED;
  hopamp3.Init.Mode = OPAMP_PGA_MODE;
  hopamp3.Init.NonInvertingInput = OPAMP_NONINVERTINGINPUT_IO1;
  hopamp3.Init.InternalOutput = ENABLE;
  hopamp3.Init.TimerControlledMuxmode = OPAMP_TIMERCONTROLLEDMUXMODE_DISABLE;
  hopamp3.Init.PgaConnect = OPAMP_PGA_CONNECT_INVERTINGINPUT_IO0_BIAS;
  hopamp3.Init.PgaGain = OPAMP_PGA_GAIN_2_OR_MINUS_1;
  hopamp3.Init.UserTrimming = OPAMP_TRIMMING_FACTORY;
  if (HAL_OPAMP_Init(&hopamp3) != HAL_OK)
  {
    Error_Handler();
  }

}

static void MX_SPI3_Init(void)
{

  /* SPI3 parameter configuration*/
  hspi3.Instance = SPI3;
  hspi3.Init.Mode = SPI_MODE_SLAVE;
  hspi3.Init.Direction = SPI_DIRECTION_2LINES;
  hspi3.Init.DataSize = SPI_DATASIZE_8BIT;
  hspi3.Init.NSS = SPI_NSS_HARD_INPUT;
  hspi3.Init.BaudRatePrescaler = SPI_BAUDRATEPRESCALER_4;
  hspi3.Init.TIMode = SPI_TIMODE_ENABLE;
  hspi3.Init.CRCCalculation = SPI_CRCCALCULATION_DISABLE;
  hspi3.Init.CRCPolynomial = 7;
  hspi3.Init.CRCLength = SPI_CRC_LENGTH_DATASIZE;
  hspi3.Init.NSSPMode = SPI_NSS_PULSE_DISABLE;
  if (HAL_SPI_Init(&hspi3) != HAL_OK)
  {
    Error_Handler();
  }

}

static void MX_TIM1_Init(void)
{

  TIM_ClockConfigTypeDef sClockSourceConfig = {0};
  TIM_MasterConfigTypeDef sMasterConfig = {0};
  TIM_OC_InitTypeDef sConfigOC = {0};
  TIM_BreakDeadTimeConfigTypeDef sBreakDeadTimeConfig = {0};

  htim1.Instance = TIM1;
  htim1.Init.Prescaler = 0;
  htim1.Init.CounterMode = TIM_COUNTERMODE_CENTERALIGNED1;
  htim1.Init.Period = 0;
  htim1.Init.ClockDivision = TIM_CLOCKDIVISION_DIV1;
  htim1.Init.RepetitionCounter = 0;
  htim1.Init.AutoReloadPreload = TIM_AUTORELOAD_PRELOAD_ENABLE;
  if (HAL_TIM_Base_Init(&htim1) != HAL_OK)
  {
    Error_Handler();
  }
  sClockSourceConfig.ClockSource = TIM_CLOCKSOURCE_INTERNAL;
  if (HAL_TIM_ConfigClockSource(&htim1, &sClockSourceConfig) != HAL_OK)
  {
    Error_Handler();
  }
  if (HAL_TIM_PWM_Init(&htim1) != HAL_OK)
  {
    Error_Handler();
  }
  sMasterConfig.MasterOutputTrigger = TIM_TRGO_RESET;
  sMasterConfig.MasterOutputTrigger2 = TIM_TRGO2_OC5REF;
  sMasterConfig.MasterSlaveMode = TIM_MASTERSLAVEMODE_DISABLE;
  if (HAL_TIMEx_MasterConfigSynchronization(&htim1, &sMasterConfig) != HAL_OK)
  {
    Error_Handler();
  }
  sConfigOC.OCMode = TIM_OCMODE_PWM1;
  sConfigOC.Pulse = 0;
  sConfigOC.OCPolarity = TIM_OCPOLARITY_HIGH;
  sConfigOC.OCNPolarity = TIM_OCNPOLARITY_HIGH;
  sConfigOC.OCFastMode = TIM_OCFAST_DISABLE;
  sConfigOC.OCIdleState = TIM_OCIDLESTATE_RESET;
  sConfigOC.OCNIdleState = TIM_OCNIDLESTATE_RESET;
  if (HAL_TIM_PWM_ConfigChannel(&htim1, &sConfigOC, TIM_CHANNEL_1) != HAL_OK)
  {
    Error_Handler();
  }
  if (HAL_TIM_PWM_ConfigChannel(&htim1, &sConfigOC, TIM_CHANNEL_2) != HAL_OK)
  {
    Error_Handler();
  }
  if (HAL_TIM_PWM_ConfigChannel(&htim1, &sConfigOC, TIM_CHANNEL_3) != HAL_OK)
  {
    Error_Handler();
  }
  if (HAL_TIM_PWM_ConfigChannel(&htim1, &sConfigOC, TIM_CHANNEL_4) != HAL_OK)
  {
    Error_Handler();
  }
  if (HAL_TIM_PWM_ConfigChannel(&htim1, &sConfigOC, TIM_CHANNEL_5) != HAL_OK)
  {
    Error_Handler();
  }
  if (HAL_TIM_PWM_ConfigChannel(&htim1, &sConfigOC, TIM_CHANNEL_6) != HAL_OK)
  {
    Error_Handler();
  }
  sBreakDeadTimeConfig.OffStateRunMode = TIM_OSSR_DISABLE;
  sBreakDeadTimeConfig.OffStateIDLEMode = TIM_OSSI_DISABLE;
  sBreakDeadTimeConfig.LockLevel = TIM_LOCKLEVEL_OFF;
  sBreakDeadTimeConfig.DeadTime = 0;
  sBreakDeadTimeConfig.BreakState = TIM_BREAK_DISABLE;
  sBreakDeadTimeConfig.BreakPolarity = TIM_BREAKPOLARITY_HIGH;
  sBreakDeadTimeConfig.BreakFilter = 0;
  sBreakDeadTimeConfig.BreakAFMode = TIM_BREAK_AFMODE_INPUT;
  sBreakDeadTimeConfig.Break2State = TIM_BREAK2_DISABLE;
  sBreakDeadTimeConfig.Break2Polarity = TIM_BREAK2POLARITY_HIGH;
  sBreakDeadTimeConfig.Break2Filter = 0;
  sBreakDeadTimeConfig.Break2AFMode = TIM_BREAK_AFMODE_INPUT;
  sBreakDeadTimeConfig.AutomaticOutput = TIM_AUTOMATICOUTPUT_DISABLE;
  if (HAL_TIMEx_ConfigBreakDeadTime(&htim1, &sBreakDeadTimeConfig) != HAL_OK)
  {
    Error_Handler();
  }
  HAL_TIM_MspPostInit(&htim1);

}

static void MX_TIM2_Init(void)
{

  TIM_ClockConfigTypeDef sClockSourceConfig = {0};
  TIM_MasterConfigTypeDef sMasterConfig = {0};
  TIM_OC_InitTypeDef sConfigOC = {0};

  htim2.Instance = TIM2;
  htim2.Init.Prescaler = 0;
  htim2.Init.CounterMode = TIM_COUNTERMODE_UP;
  htim2.Init.Period = 65535;
  htim2.Init.ClockDivision = TIM_CLOCKDIVISION_DIV1;
  htim2.Init.AutoReloadPreload = TIM_AUTORELOAD_PRELOAD_DISABLE;
  if (HAL_TIM_Base_Init(&htim2) != HAL_OK)
  {
    Error_Handler();
  }
  sClockSourceConfig.ClockSource = TIM_CLOCKSOURCE_INTERNAL;
  if (HAL_TIM_ConfigClockSource(&htim2, &sClockSourceConfig) != HAL_OK)
  {
    Error_Handler();
  }
  if (HAL_TIM_PWM_Init(&htim2) != HAL_OK)
  {
    Error_Handler();
  }
  sMasterConfig.MasterOutputTrigger = TIM_TRGO_RESET;
  sMasterConfig.MasterSlaveMode = TIM_MASTERSLAVEMODE_DISABLE;
  if (HAL_TIMEx_MasterConfigSynchronization(&htim2, &sMasterConfig) != HAL_OK)
  {
    Error_Handler();
  }
  sConfigOC.OCMode = TIM_OCMODE_PWM1;
  sConfigOC.Pulse = 0;
  sConfigOC.OCPolarity = TIM_OCPOLARITY_LOW;
  sConfigOC.OCFastMode = TIM_OCFAST_DISABLE;
  if (HAL_TIM_PWM_ConfigChannel(&htim2, &sConfigOC, TIM_CHANNEL_3) != HAL_OK)
  {
    Error_Handler();
  }
  HAL_TIM_MspPostInit(&htim2);

}

static void MX_TIM3_Init(void)
{

  TIM_ClockConfigTypeDef sClockSourceConfig = {0};
  TIM_HallSensor_InitTypeDef sConfig = {0};
  TIM_MasterConfigTypeDef sMasterConfig = {0};

  htim3.Instance = TIM3;
  htim3.Init.Prescaler = 0;
  htim3.Init.CounterMode = TIM_COUNTERMODE_UP;
  htim3.Init.Period = 65535;
  htim3.Init.ClockDivision = TIM_CLOCKDIVISION_DIV1;
  htim3.Init.AutoReloadPreload = TIM_AUTORELOAD_PRELOAD_DISABLE;
  if (HAL_TIM_Base_Init(&htim3) != HAL_OK)
  {
    Error_Handler();
  }
  sClockSourceConfig.ClockSource = TIM_CLOCKSOURCE_INTERNAL;
  if (HAL_TIM_ConfigClockSource(&htim3, &sClockSourceConfig) != HAL_OK)
  {
    Error_Handler();
  }
  sConfig.IC1Polarity = TIM_ICPOLARITY_RISING;
  sConfig.IC1Prescaler = TIM_ICPSC_DIV1;
  sConfig.IC1Filter = 0;
  sConfig.Commutation_Delay = 0;
  if (HAL_TIMEx_HallSensor_Init(&htim3, &sConfig) != HAL_OK)
  {
    Error_Handler();
  }
  sMasterConfig.MasterOutputTrigger = TIM_TRGO_OC2REF;
  sMasterConfig.MasterSlaveMode = TIM_MASTERSLAVEMODE_DISABLE;
  if (HAL_TIMEx_MasterConfigSynchronization(&htim3, &sMasterConfig) != HAL_OK)
  {
    Error_Handler();
  }

}

static void MX_TIM4_Init(void)
{

  TIM_ClockConfigTypeDef sClockSourceConfig = {0};
  TIM_MasterConfigTypeDef sMasterConfig = {0};
  TIM_OC_InitTypeDef sConfigOC = {0};

  htim4.Instance = TIM4;
  htim4.Init.Prescaler = 0;
  htim4.Init.CounterMode = TIM_COUNTERMODE_UP;
  htim4.Init.Period = 65535;
  htim4.Init.ClockDivision = TIM_CLOCKDIVISION_DIV1;
  htim4.Init.AutoReloadPreload = TIM_AUTORELOAD_PRELOAD_DISABLE;
  if (HAL_TIM_Base_Init(&htim4) != HAL_OK)
  {
    Error_Handler();
  }
  sClockSourceConfig.ClockSource = TIM_CLOCKSOURCE_INTERNAL;
  if (HAL_TIM_ConfigClockSource(&htim4, &sClockSourceConfig) != HAL_OK)
  {
    Error_Handler();
  }
  if (HAL_TIM_PWM_Init(&htim4) != HAL_OK)
  {
    Error_Handler();
  }
  sMasterConfig.MasterOutputTrigger = TIM_TRGO_RESET;
  sMasterConfig.MasterSlaveMode = TIM_MASTERSLAVEMODE_DISABLE;
  if (HAL_TIMEx_MasterConfigSynchronization(&htim4, &sMasterConfig) != HAL_OK)
  {
    Error_Handler();
  }
  sConfigOC.OCMode = TIM_OCMODE_PWM1;
  sConfigOC.Pulse = 0;
  sConfigOC.OCPolarity = TIM_OCPOLARITY_LOW;
  sConfigOC.OCFastMode = TIM_OCFAST_DISABLE;
  if (HAL_TIM_PWM_ConfigChannel(&htim4, &sConfigOC, TIM_CHANNEL_1) != HAL_OK)
  {
    Error_Handler();
  }
  if (HAL_TIM_PWM_ConfigChannel(&htim4, &sConfigOC, TIM_CHANNEL_2) != HAL_OK)
  {
    Error_Handler();
  }
  HAL_TIM_MspPostInit(&htim4);

}

static void MX_USART3_UART_Init(void)
{

  huart3.Instance = USART3;
  huart3.Init.BaudRate = 115200;
  huart3.Init.WordLength = UART_WORDLENGTH_8B;
  huart3.Init.StopBits = UART_STOPBITS_1;
  huart3.Init.Parity = UART_PARITY_NONE;
  huart3.Init.Mode = UART_MODE_TX_RX;
  huart3.Init.HwFlowCtl = UART_HWCONTROL_NONE;
  huart3.Init.OverSampling = UART_OVERSAMPLING_16;
  huart3.Init.OneBitSampling = UART_ONE_BIT_SAMPLE_DISABLE;
  huart3.Init.ClockPrescaler = UART_PRESCALER_DIV1;
  huart3.AdvancedInit.AdvFeatureInit = UART_ADVFEATURE_NO_INIT;
  if (HAL_UART_Init(&huart3) != HAL_OK)
  {
    Error_Handler();
  }
  if (HAL_UARTEx_SetTxFifoThreshold(&huart3, UART_TXFIFO_THRESHOLD_1_8) != HAL_OK)
  {
    Error_Handler();
  }
  if (HAL_UARTEx_SetRxFifoThreshold(&huart3, UART_RXFIFO_THRESHOLD_1_8) != HAL_OK)
  {
    Error_Handler();
  }
  if (HAL_UARTEx_DisableFifoMode(&huart3) != HAL_OK)
  {
    Error_Handler();
  }

}

static void MX_GPIO_Init(void)
{
  GPIO_InitTypeDef GPIO_InitStruct = {0};

  /* GPIO Ports Clock Enable */
  __HAL_RCC_GPIOC_CLK_ENABLE();
  __HAL_RCC_GPIOF_CLK_ENABLE();
  __HAL_RCC_GPIOA_CLK_ENABLE();
  __HAL_RCC_GPIOB_CLK_ENABLE();
  __HAL_RCC_GPIOD_CLK_ENABLE();

  /*Configure GPIO pins : PC14 PC15 */
  GPIO_InitStruct.Pin = GPIO_PIN_14|GPIO_PIN_15;
  GPIO_InitStruct.Mode = GPIO_MODE_INPUT;
  GPIO_InitStruct.Pull = GPIO_NOPULL;
  HAL_GPIO_Init(GPIOC, &GPIO_InitStruct);

  /*Configure GPIO pin : PD2 */
  GPIO_InitStruct.Pin = GPIO_PIN_2;
  GPIO_InitStruct.Mode = GPIO_MODE_INPUT;
  GPIO_InitStruct.Pull = GPIO_NOPULL;
  HAL_GPIO_Init(GPIOD, &GPIO_InitStruct);

  /*Configure GPIO pin : PB5 */
  GPIO_InitStruct.Pin = GPIO_PIN_5;
  GPIO_InitStruct.Mode = GPIO_MODE_INPUT;
  GPIO_InitStruct.Pull = GPIO_NOPULL;
  HAL_GPIO_Init(GPIOB, &GPIO_InitStruct);

}

void HAL_TIM_PeriodElapsedCallback(TIM_HandleTypeDef *htim)
{
  if (htim->Instance == TIM8)
  {
    HAL_IncTick();
  }
}

void Error_Handler(void)
{
  __disable_irq();
  while (1)
  {
  }
}
